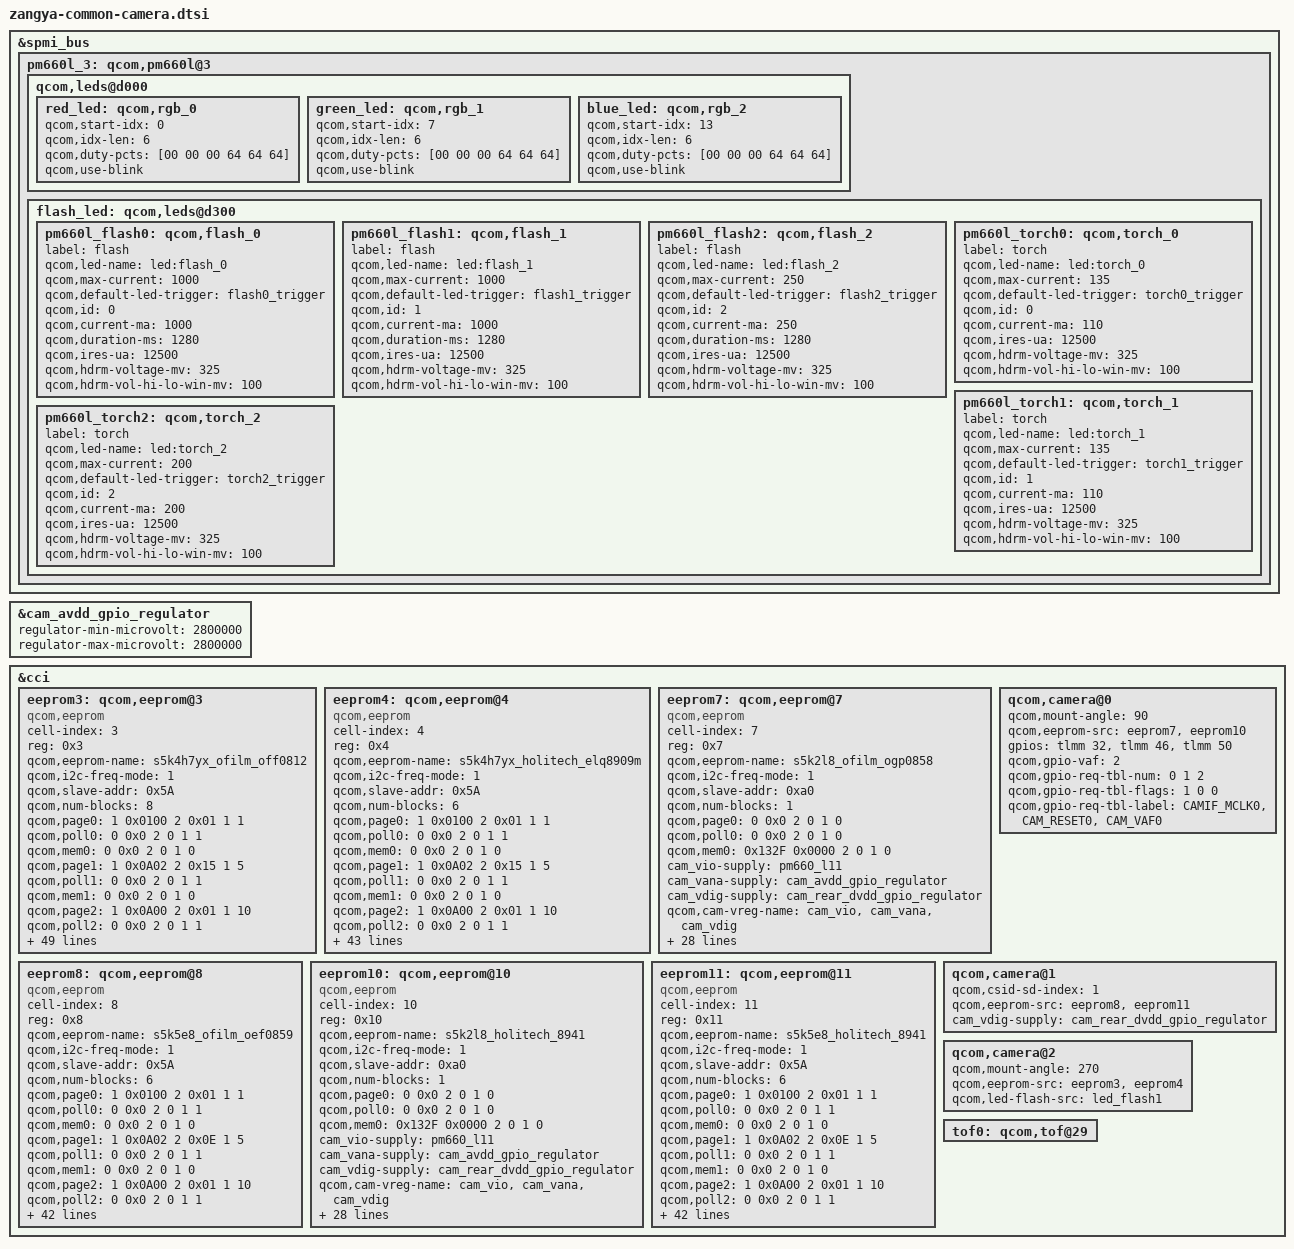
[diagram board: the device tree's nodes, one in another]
/*
 * Copyright (c) 2016-2017, The Linux Foundation. All rights reserved.
 * Copyright (c) 2019, The bq project. All rights reserved.
 *
 * This program is free software; you can redistribute it and/or modify
 * it under the terms of the GNU General Public License version 2 and
 * only version 2 as published by the Free Software Foundation.
 *
 * This program is distributed in the hope that it will be useful,
 * but WITHOUT ANY WARRANTY; without even the implied warranty of
 * MERCHANTABILITY or FITNESS FOR A PARTICULAR PURPOSE.  See the
 * GNU General Public License for more details.
 */

&spmi_bus {
	pm660l_3: qcom,pm660l@3 {
		qcom,leds@d000 {
			red_led: qcom,rgb_0 {
				qcom,start-idx = <0>;
				qcom,idx-len = <6>;
				qcom,duty-pcts =
				[00 00 00 64 64 64];
				qcom,use-blink;
			};

			green_led: qcom,rgb_1 {
				qcom,start-idx = <7>;
				qcom,idx-len = <6>;
				qcom,duty-pcts =
				[00 00 00 64 64 64];
				qcom,use-blink;
			};

			blue_led: qcom,rgb_2 {
				qcom,start-idx = <13>;
				qcom,idx-len = <6>;
				qcom,duty-pcts =
				[00 00 00 64 64 64];
				qcom,use-blink;
			};

		};

		flash_led: qcom,leds@d300 {
			pm660l_flash0: qcom,flash_0 {
				label = "flash";
				qcom,led-name = "led:flash_0";
				qcom,max-current = <1000>;
				qcom,default-led-trigger = "flash0_trigger";
				qcom,id = <0>;
				qcom,current-ma = <1000>;
				qcom,duration-ms = <1280>;
				qcom,ires-ua = <12500>;
				qcom,hdrm-voltage-mv = <325>;
				qcom,hdrm-vol-hi-lo-win-mv = <100>;
			};

			pm660l_flash1: qcom,flash_1 {
				label = "flash";
				qcom,led-name = "led:flash_1";
				qcom,max-current = <1000>;
				qcom,default-led-trigger = "flash1_trigger";
				qcom,id = <1>;
				qcom,current-ma = <1000>;
				qcom,duration-ms = <1280>;
				qcom,ires-ua = <12500>;
				qcom,hdrm-voltage-mv = <325>;
				qcom,hdrm-vol-hi-lo-win-mv = <100>;
			};

			pm660l_flash2: qcom,flash_2 {
				label = "flash";
				qcom,led-name = "led:flash_2";
				qcom,max-current = <250>;
				qcom,default-led-trigger = "flash2_trigger";
				qcom,id = <2>;
				qcom,current-ma = <250>;
				qcom,duration-ms = <1280>;
				qcom,ires-ua = <12500>;
				qcom,hdrm-voltage-mv = <325>;
				qcom,hdrm-vol-hi-lo-win-mv = <100>;
			};

			pm660l_torch0: qcom,torch_0 {
				label = "torch";
				qcom,led-name = "led:torch_0";
				qcom,max-current = <135>;
				qcom,default-led-trigger = "torch0_trigger";
				qcom,id = <0>;
				qcom,current-ma = <110>;
				qcom,ires-ua = <12500>;
				qcom,hdrm-voltage-mv = <325>;
				qcom,hdrm-vol-hi-lo-win-mv = <100>;
			};

			pm660l_torch1: qcom,torch_1 {
				label = "torch";
				qcom,led-name = "led:torch_1";
				qcom,max-current = <135>;
				qcom,default-led-trigger = "torch1_trigger";
				qcom,id = <1>;
				qcom,current-ma = <110>;
				qcom,ires-ua = <12500>;
				qcom,hdrm-voltage-mv = <325>;
				qcom,hdrm-vol-hi-lo-win-mv = <100>;
			};

			pm660l_torch2: qcom,torch_2 {
				label = "torch";
				qcom,led-name = "led:torch_2";
				qcom,max-current = <200>;
				qcom,default-led-trigger = "torch2_trigger";
				qcom,id = <2>;
				qcom,current-ma = <200>;
				qcom,ires-ua = <12500>;
				qcom,hdrm-voltage-mv = <325>;
				qcom,hdrm-vol-hi-lo-win-mv = <100>;
			};

		};
	};
};

&cam_avdd_gpio_regulator {
	regulator-min-microvolt = <2800000>;
	regulator-max-microvolt = <2800000>;
};

&cci {
	eeprom3: qcom,eeprom@3 {
		cell-index = <3>;
		reg = <0x3>;
		qcom,eeprom-name = "s5k4h7yx_ofilm_off0812";
		compatible = "qcom,eeprom";
		qcom,i2c-freq-mode = <1>;
		qcom,slave-addr = <0x5A>;
		qcom,num-blocks = <8>;

		//init otp
		qcom,page0 = <1 0x0100 2 0x01 1 1>;
		qcom,poll0 = <0 0x0 2 0 1 1>;
		qcom,mem0 = <0 0x0 2 0 1 0>;

		//set page 21
		qcom,page1 = <1 0x0A02 2 0x15 1 5>;
		qcom,poll1 = <0 0x0 2 0 1 1>;
		qcom,mem1 = <0 0x0 2 0 1 0>;

		//read value
		qcom,page2 = <1 0x0A00 2 0x01 1 10>;
		qcom,poll2 = <0 0x0 2 0 1 1>;
		qcom,mem2 = <34 0x0A04 2 0 1 0>;

		//set page 22
		qcom,page3 = <1 0x0A02 2 0x16 1 1>;
		qcom,poll3 = <0 0x0 2 0 1 1>;
		qcom,mem3 = <0 0x0 2 0 1 0>;

		//read value
		qcom,page4 = <1 0x0A00 2 0x01 1 5>;
		qcom,poll4 = <0 0x00 2 0 1 1>;
		qcom,mem4 = <64 0x0A04 2 0 1 0>;

		//set page 23
		qcom,page5 = <1 0x0A02 2 0x17 1 1>;
		qcom,poll5= <0 0x0 2 0 1 1>;
		qcom,mem5 = <0 0x0 2 0 1 0>;

		//read value
		qcom,page6= <1 0x0A00 2 0x01 1 5>;
		qcom,poll6 = <0 0x00 2 0 1 1>;
		qcom,mem6 = <64 0x0A04 2 0 1 0>;

		//Disable NVM controller
		qcom,page7 = <1 0x0A00 2 0x00 1 1>;
		qcom,poll7 = <0 0x0 2 0 1 1>;
		qcom,mem7 = <0 0x0 2 0 1 0>;

		cam_vio-supply = <&pm660_l11>;//1.8
		cam_vana-supply = <&cam_avdd_gpio_regulator>;//2.8
		cam_vdig-supply = <&cam_dvdd_gpio_regulator>;//1.2
		qcom,cam-vreg-name = "cam_vio", "cam_vana", "cam_vdig";
		qcom,cam-vreg-min-voltage = <1780000 0 0>;
		qcom,cam-vreg-max-voltage = <1950000 0 0>;
		qcom,cam-vreg-op-mode = <105000 0 0>;
		qcom,gpio-no-mux = <0>;
		pinctrl-names = "cam_default", "cam_suspend";
		pinctrl-0 = <&cam_sensor_mclk1_active
				 &cam_sensor_front_active>;
		pinctrl-1 = <&cam_sensor_mclk1_suspend
				 &cam_sensor_front_suspend>;
		gpios = <&tlmm 33 0>,
			<&tlmm 47 0>;
		qcom,gpio-reset = <1>;
		qcom,gpio-req-tbl-num = <0 1>;
		qcom,gpio-req-tbl-flags = <1 0>;
		qcom,gpio-req-tbl-label = "CAMIF_MCLK2",
					"CAM_RESET2";
		qcom,cam-power-seq-type = "sensor_gpio","sensor_vreg","sensor_vreg","sensor_vreg","sensor_clk","sensor_gpio";
		qcom,cam-power-seq-val = "sensor_gpio_reset","cam_vana","cam_vdig","cam_vio","sensor_cam_mclk","sensor_gpio_reset";
		qcom,cam-power-seq-cfg-val = <0 1 1 1 24000000 1>;
		qcom,cam-power-seq-delay =    <1 5 5 5 1 10>;
		qcom,sensor-position = <1>;
		qcom,sensor-mode = <0>;
		qcom,cci-master = <1>;
		status = "ok";
		clocks = <&clock_mmss MCLK1_CLK_SRC>,
			<&clock_mmss MMSS_CAMSS_MCLK1_CLK>;
		clock-names = "cam_src_clk", "cam_clk";
		qcom,clock-rates = <24000000 0>;
	};

	eeprom4: qcom,eeprom@4 {
		cell-index = <4>;
		reg = <0x4>;
		qcom,eeprom-name = "s5k4h7yx_holitech_elq8909m";
		compatible = "qcom,eeprom";
		qcom,i2c-freq-mode = <1>;
		qcom,slave-addr = <0x5A>;
		qcom,num-blocks = <6>;

		//init otp
		qcom,page0 = <1 0x0100 2 0x01 1 1>;
		qcom,poll0 = <0 0x0 2 0 1 1>;
		qcom,mem0 = <0 0x0 2 0 1 0>;

		//set page 21
		qcom,page1 = <1 0x0A02 2 0x15 1 5>;
		qcom,poll1 = <0 0x0 2 0 1 1>;
		qcom,mem1 = <0 0x0 2 0 1 0>;

		//read value
		qcom,page2 = <1 0x0A00 2 0x01 1 10>;
		qcom,poll2 = <0 0x0 2 0 1 1>;
		qcom,mem2 = <62 0x0A04 2 0 1 0>;

		//set page 22
		qcom,page3 = <1 0x0A02 2 0x16 1 1>;
		qcom,poll3 = <0 0x0 2 0 1 1>;
		qcom,mem3 = <0 0x0 2 0 1 0>;

		//read value
		qcom,page4 = <1 0x0A00 2 0x01 1 5>;
		qcom,poll4 = <0 0x00 2 0 1 1>;
		qcom,mem4 = <44 0x0A04 2 0 1 0>;

		//Disable NVM controller
		qcom,page5 = <1 0x0A00 2 0x00 1 1>;
		qcom,poll5 = <0 0x0 2 0 1 1>;
		qcom,mem5 = <0 0x0 2 0 1 0>;

		cam_vio-supply = <&pm660_l11>;//1.8
		cam_vana-supply = <&cam_avdd_gpio_regulator>;//2.8
		cam_vdig-supply = <&cam_dvdd_gpio_regulator>;//1.2
		qcom,cam-vreg-name = "cam_vio", "cam_vana", "cam_vdig";
		qcom,cam-vreg-min-voltage = <1780000 0 0>;
		qcom,cam-vreg-max-voltage = <1950000 0 0>;
		qcom,cam-vreg-op-mode = <105000 0 0>;
		qcom,gpio-no-mux = <0>;
		pinctrl-names = "cam_default", "cam_suspend";
		pinctrl-0 = <&cam_sensor_mclk1_active
				 &cam_sensor_front_active>;
		pinctrl-1 = <&cam_sensor_mclk1_suspend
				 &cam_sensor_front_suspend>;
		gpios = <&tlmm 33 0>,
			<&tlmm 47 0>;
		qcom,gpio-reset = <1>;
		qcom,gpio-req-tbl-num = <0 1>;
		qcom,gpio-req-tbl-flags = <1 0>;
		qcom,gpio-req-tbl-label = "CAMIF_MCLK2",
					"CAM_RESET2";
		qcom,cam-power-seq-type = "sensor_gpio","sensor_vreg","sensor_vreg","sensor_vreg","sensor_clk","sensor_gpio";
		qcom,cam-power-seq-val = "sensor_gpio_reset","cam_vana","cam_vdig","cam_vio","sensor_cam_mclk","sensor_gpio_reset";
		qcom,cam-power-seq-cfg-val = <0 1 1 1 24000000 1>;
		qcom,cam-power-seq-delay =    <1 5 5 5 1 10>;
		qcom,sensor-position = <1>;
		qcom,sensor-mode = <0>;
		qcom,cci-master = <1>;
		status = "ok";
		clocks = <&clock_mmss MCLK1_CLK_SRC>,
			<&clock_mmss MMSS_CAMSS_MCLK1_CLK>;
		clock-names = "cam_src_clk", "cam_clk";
		qcom,clock-rates = <24000000 0>;
	};

	eeprom7: qcom,eeprom@7 {
		cell-index = <7>;
		reg = <0x7>;
		qcom,eeprom-name = "s5k2l8_ofilm_ogp0858";
		compatible = "qcom,eeprom";
		qcom,i2c-freq-mode = <1>;
		qcom,slave-addr = <0xa0>;
		qcom,num-blocks = <1>;
		qcom,page0 = <0 0x0 2 0 1 0>;
		qcom,poll0 = <0 0x0 2 0 1 0>;
		qcom,mem0 = <0x132F 0x0000 2 0 1 0>;

		cam_vio-supply = <&pm660_l11>;//1.8
		cam_vana-supply = <&cam_avdd_gpio_regulator>;//2.8
		cam_vdig-supply = <&cam_rear_dvdd_gpio_regulator>;//1.2
		qcom,cam-vreg-name = "cam_vio", "cam_vana", "cam_vdig";
		qcom,cam-vreg-min-voltage = <1780000 0 0>;
		qcom,cam-vreg-max-voltage = <1950000 0 0>;
		qcom,cam-vreg-op-mode = <105000 0 0>;
		qcom,gpio-no-mux = <0>;
		pinctrl-names = "cam_default", "cam_suspend";
		pinctrl-0 = <&cam_sensor_mclk0_active
				 &cam_sensor_rear_active>;
		pinctrl-1 = <&cam_sensor_mclk0_suspend
				 &cam_sensor_rear_suspend>;
		gpios = <&tlmm 32 0>,
			<&tlmm 46 0>;
		qcom,gpio-reset = <1>;
		qcom,gpio-req-tbl-num = <0 1>;
		qcom,gpio-req-tbl-flags = <1 0>;
		qcom,gpio-req-tbl-label = "CAMIF_MCLK0",
					  "CAM_RESET0";
		qcom,cam-power-seq-type = "sensor_gpio","sensor_vreg","sensor_vreg","sensor_vreg","sensor_clk","sensor_gpio";
		qcom,cam-power-seq-val = "sensor_gpio_reset","cam_vana","cam_vdig","cam_vio","sensor_cam_mclk","sensor_gpio_reset";
		qcom,cam-power-seq-cfg-val = <0 1 1 1 24000000 1>;
		qcom,cam-power-seq-delay =    <1 5 5 5 1 10>;
		qcom,sensor-position = <0>;
		qcom,sensor-mode = <0>;
		qcom,cci-master = <0>;
		status = "ok";
		clocks = <&clock_mmss MCLK0_CLK_SRC>,
				<&clock_mmss MMSS_CAMSS_MCLK0_CLK>;
		clock-names = "cam_src_clk", "cam_clk";
		qcom,clock-rates = <24000000 0>;
	};

	eeprom8: qcom,eeprom@8 {
		cell-index = <8>;
		reg = <0x8>;
		qcom,eeprom-name = "s5k5e8_ofilm_oef0859";
		compatible = "qcom,eeprom";
		qcom,i2c-freq-mode = <1>;
		qcom,slave-addr = <0x5A>;
		qcom,num-blocks = <6>;

		//init otp
		qcom,page0 = <1 0x0100 2 0x01 1 1>;
		qcom,poll0 = <0 0x0 2 0 1 1>;
		qcom,mem0 = <0 0x0 2 0 1 0>;

		//set page 14
		qcom,page1 = <1 0x0A02 2 0x0E 1 5>;
		qcom,poll1 = <0 0x0 2 0 1 1>;
		qcom,mem1 = <0 0x0 2 0 1 0>;

		//read value
		qcom,page2 = <1 0x0A00 2 0x01 1 10>;
		qcom,poll2 = <0 0x0 2 0 1 1>;
		qcom,mem2 = <58 0x0A04 2 0 1 0>;

		//set page 15
		qcom,page3 = <1 0x0A02 2 0x0F 1 1>;
		qcom,poll3 = <0 0x0 2 0 1 1>;
		qcom,mem3 = <0 0x0 2 0 1 0>;

		//read value
		qcom,page4 = <1 0x0A00 2 0x01 1 5>;
		qcom,poll4 = <0 0x00 2 0 1 1>;
		qcom,mem4 = <44 0x0A04 2 0 1 0>;

		//Disable NVM controller
		qcom,page5 = <1 0x0A00 2 0x00 1 1>;
		qcom,poll5 = <0 0x0 2 0 1 1>;
		qcom,mem5 = <0 0x0 2 0 1 0>;

		cam_vio-supply = <&pm660_l11>;//1.8
		cam_vana-supply = <&cam_avdd_gpio_regulator>;//2.8
		cam_vdig-supply = <&cam_rear_dvdd_gpio_regulator>;//1.2
		qcom,cam-vreg-name = "cam_vio", "cam_vana", "cam_vdig";
		qcom,cam-vreg-min-voltage = <1780000 0 0>;
		qcom,cam-vreg-max-voltage = <1950000 0 0>;
		qcom,cam-vreg-op-mode = <105000 0 0>;
		qcom,gpio-no-mux = <0>;
		pinctrl-names = "cam_default", "cam_suspend";
		pinctrl-0 = <&cam_sensor_mclk2_active
				 &cam_sensor_rear2_active>;
		pinctrl-1 = <&cam_sensor_mclk2_suspend
				 &cam_sensor_rear2_suspend>;
		gpios = <&tlmm 34 0>,
			<&tlmm 48 0>;
		qcom,gpio-reset = <1>;
		qcom,gpio-req-tbl-num = <0 1>;
		qcom,gpio-req-tbl-flags = <1 0>;
		qcom,gpio-req-tbl-label = "CAMIF_MCLK",
					  "CAM_RESET";
		qcom,cam-power-seq-type = "sensor_gpio","sensor_vreg","sensor_vreg","sensor_vreg","sensor_clk","sensor_gpio";
		qcom,cam-power-seq-val = "sensor_gpio_reset","cam_vana","cam_vdig","cam_vio","sensor_cam_mclk","sensor_gpio_reset";
		qcom,cam-power-seq-cfg-val = <0 1 1 1 24000000 1>;
		qcom,cam-power-seq-delay =    <1 5 5 5 1 10>;
		qcom,sensor-position = <0>;
		qcom,sensor-mode = <0>;
		qcom,cci-master = <1>;
		status = "ok";
		clocks = <&clock_mmss MCLK2_CLK_SRC>,
			<&clock_mmss MMSS_CAMSS_MCLK2_CLK>;
		clock-names = "cam_src_clk", "cam_clk";
		qcom,clock-rates = <24000000 0>;
	};

	eeprom10: qcom,eeprom@10 {
		cell-index = <10>;
		reg = <0x10>;
		qcom,eeprom-name = "s5k2l8_holitech_8941";
		compatible = "qcom,eeprom";
		qcom,i2c-freq-mode = <1>;
		qcom,slave-addr = <0xa0>;
		qcom,num-blocks = <1>;
		qcom,page0 = <0 0x0 2 0 1 0>;
		qcom,poll0 = <0 0x0 2 0 1 0>;
		qcom,mem0 = <0x132F 0x0000 2 0 1 0>;

		cam_vio-supply = <&pm660_l11>;//1.8
		cam_vana-supply = <&cam_avdd_gpio_regulator>;//2.8
		cam_vdig-supply = <&cam_rear_dvdd_gpio_regulator>;//1.2
		qcom,cam-vreg-name = "cam_vio", "cam_vana", "cam_vdig";
		qcom,cam-vreg-min-voltage = <1780000 0 0>;
		qcom,cam-vreg-max-voltage = <1950000 0 0>;
		qcom,cam-vreg-op-mode = <105000 0 0>;
		qcom,gpio-no-mux = <0>;
		pinctrl-names = "cam_default", "cam_suspend";
		pinctrl-0 = <&cam_sensor_mclk0_active
				 &cam_sensor_rear_active>;
		pinctrl-1 = <&cam_sensor_mclk0_suspend
				 &cam_sensor_rear_suspend>;
		gpios = <&tlmm 32 0>,
			<&tlmm 46 0>;
		qcom,gpio-reset = <1>;
		qcom,gpio-req-tbl-num = <0 1>;
		qcom,gpio-req-tbl-flags = <1 0>;
		qcom,gpio-req-tbl-label = "CAMIF_MCLK0",
					  "CAM_RESET0";
		qcom,cam-power-seq-type = "sensor_gpio","sensor_vreg","sensor_vreg","sensor_vreg","sensor_clk","sensor_gpio";
		qcom,cam-power-seq-val = "sensor_gpio_reset","cam_vana","cam_vdig","cam_vio","sensor_cam_mclk","sensor_gpio_reset";
		qcom,cam-power-seq-cfg-val = <0 1 1 1 24000000 1>;
		qcom,cam-power-seq-delay =    <1 5 5 5 1 10>;
		qcom,sensor-position = <0>;
		qcom,sensor-mode = <0>;
		qcom,cci-master = <0>;
		status = "ok";
		clocks = <&clock_mmss MCLK0_CLK_SRC>,
				<&clock_mmss MMSS_CAMSS_MCLK0_CLK>;
		clock-names = "cam_src_clk", "cam_clk";
		qcom,clock-rates = <24000000 0>;
	};

	eeprom11: qcom,eeprom@11 {
		cell-index = <11>;
		reg = <0x11>;
		qcom,eeprom-name = "s5k5e8_holitech_8941";
		compatible = "qcom,eeprom";
		qcom,i2c-freq-mode = <1>;
		qcom,slave-addr = <0x5A>;
		qcom,num-blocks = <6>;

		//init otp
		qcom,page0 = <1 0x0100 2 0x01 1 1>;
		qcom,poll0 = <0 0x0 2 0 1 1>;
		qcom,mem0 = <0 0x0 2 0 1 0>;

		//set page 14
		qcom,page1 = <1 0x0A02 2 0x0E 1 5>;
		qcom,poll1 = <0 0x0 2 0 1 1>;
		qcom,mem1 = <0 0x0 2 0 1 0>;

		//read value
		qcom,page2 = <1 0x0A00 2 0x01 1 10>;
		qcom,poll2 = <0 0x0 2 0 1 1>;
		qcom,mem2 = <58 0x0A04 2 0 1 0>;

		//set page 15
		qcom,page3 = <1 0x0A02 2 0x0F 1 1>;
		qcom,poll3 = <0 0x0 2 0 1 1>;
		qcom,mem3 = <0 0x0 2 0 1 0>;

		//read value
		qcom,page4 = <1 0x0A00 2 0x01 1 5>;
		qcom,poll4 = <0 0x00 2 0 1 1>;
		qcom,mem4 = <44 0x0A04 2 0 1 0>;

		//Disable NVM controller
		qcom,page5 = <1 0x0A00 2 0x00 1 1>;
		qcom,poll5 = <0 0x0 2 0 1 1>;
		qcom,mem5 = <0 0x0 2 0 1 0>;

		cam_vio-supply = <&pm660_l11>;//1.8
		cam_vana-supply = <&cam_avdd_gpio_regulator>;//2.8
		cam_vdig-supply = <&cam_rear_dvdd_gpio_regulator>;//1.2
		qcom,cam-vreg-name = "cam_vio", "cam_vana", "cam_vdig";
		qcom,cam-vreg-min-voltage = <1780000 0 0>;
		qcom,cam-vreg-max-voltage = <1950000 0 0>;
		qcom,cam-vreg-op-mode = <105000 0 0>;
		qcom,gpio-no-mux = <0>;
		pinctrl-names = "cam_default", "cam_suspend";
		pinctrl-0 = <&cam_sensor_mclk2_active
				 &cam_sensor_rear2_active>;
		pinctrl-1 = <&cam_sensor_mclk2_suspend
				 &cam_sensor_rear2_suspend>;
		gpios = <&tlmm 34 0>,
			<&tlmm 48 0>;
		qcom,gpio-reset = <1>;
		qcom,gpio-req-tbl-num = <0 1>;
		qcom,gpio-req-tbl-flags = <1 0>;
		qcom,gpio-req-tbl-label = "CAMIF_MCLK",
					  "CAM_RESET";
		qcom,cam-power-seq-type = "sensor_gpio","sensor_vreg","sensor_vreg","sensor_vreg","sensor_clk","sensor_gpio";
		qcom,cam-power-seq-val = "sensor_gpio_reset","cam_vana","cam_vdig","cam_vio","sensor_cam_mclk","sensor_gpio_reset";
		qcom,cam-power-seq-cfg-val = <0 1 1 1 24000000 1>;
		qcom,cam-power-seq-delay =    <1 5 5 5 1 10>;
		qcom,sensor-position = <0>;
		qcom,sensor-mode = <0>;
		qcom,cci-master = <1>;
		status = "ok";
		clocks = <&clock_mmss MCLK2_CLK_SRC>,
			<&clock_mmss MMSS_CAMSS_MCLK2_CLK>;
		clock-names = "cam_src_clk", "cam_clk";
		qcom,clock-rates = <24000000 0>;
	};

	qcom,camera@0 {
		qcom,mount-angle = <90>;
		qcom,eeprom-src = <&eeprom7 &eeprom10>;
			gpios = <&tlmm 32 0>,
				<&tlmm 46 0>,
				<&tlmm 50 0>;
		qcom,gpio-vaf = <2>;
		qcom,gpio-req-tbl-num = <0 1 2>;
		qcom,gpio-req-tbl-flags = <1 0 0>;
		qcom,gpio-req-tbl-label = "CAMIF_MCLK0",
					"CAM_RESET0",
					"CAM_VAF0";
		/delete-property/ qcom,ois-src;
	};

	qcom,camera@1 {
		qcom,csid-sd-index = <1>;
		qcom,eeprom-src = <&eeprom8 &eeprom11>;
		cam_vdig-supply = <&cam_rear_dvdd_gpio_regulator>;
		/delete-property/ qcom,led-flash-src;
	};

	qcom,camera@2 {
		qcom,mount-angle = <270>;
		qcom,eeprom-src = <&eeprom3 &eeprom4>;
		qcom,led-flash-src = <&led_flash1>;
		/delete-property/ qcom,actuator-src;
	};

	tof0: qcom,tof@29 {
		/delete-property/ stm,irq-gpio;
	};
};
